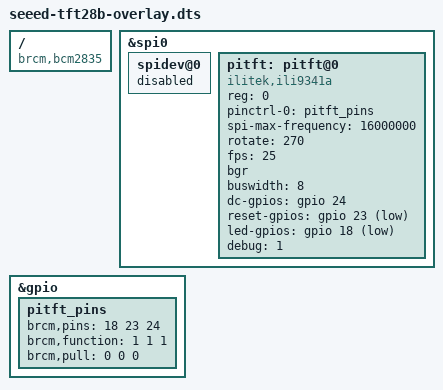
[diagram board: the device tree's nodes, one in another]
/*
 * Device Tree overlay for Seeed 2.8" resistive touch screen
 *
 */

/dts-v1/;
/plugin/;

/ {
	compatible = "brcm,bcm2835", "brcm,bcm2708", "brcm,bcm2709";

	fragment@0 {
		target = <&spi0>;
		__overlay__ {
			status = "okay";

			spidev@0{
				status = "disabled";
			};
		};
	};

	fragment@1 {
		target = <&gpio>;
		__overlay__ {
			pitft_pins: pitft_pins {
				brcm,pins = <18 23 24>;
				brcm,function = <1 1 1>; /* in out */
				brcm,pull = <0 0 0>; /* pullup none */
			};
		};
	};

	fragment@2 {
		target = <&spi0>;
		__overlay__ {
			/* needed to avoid dtc warning */
			#address-cells = <1>;
			#size-cells = <0>;

			pitft: pitft@0{
				compatible = "ilitek,ili9341a";
				reg = <0>;
				pinctrl-names = "default";
				pinctrl-0 = <&pitft_pins>;

				spi-max-frequency = <16000000>;
				rotate = <270>;
				fps = <25>;
				bgr;
				buswidth = <8>;
				dc-gpios = <&gpio 24 0>;
				reset-gpios = <&gpio 23 1>;
				led-gpios = <&gpio 18 1>;
				debug = <1>;
			};
		};
	};

	__overrides__ {
		speed =   <&pitft>,"spi-max-frequency:0";
		rotate =  <&pitft>,"rotate:0";
		fps =     <&pitft>,"fps:0";
		debug =   <&pitft>,"debug:0";
	};
};
